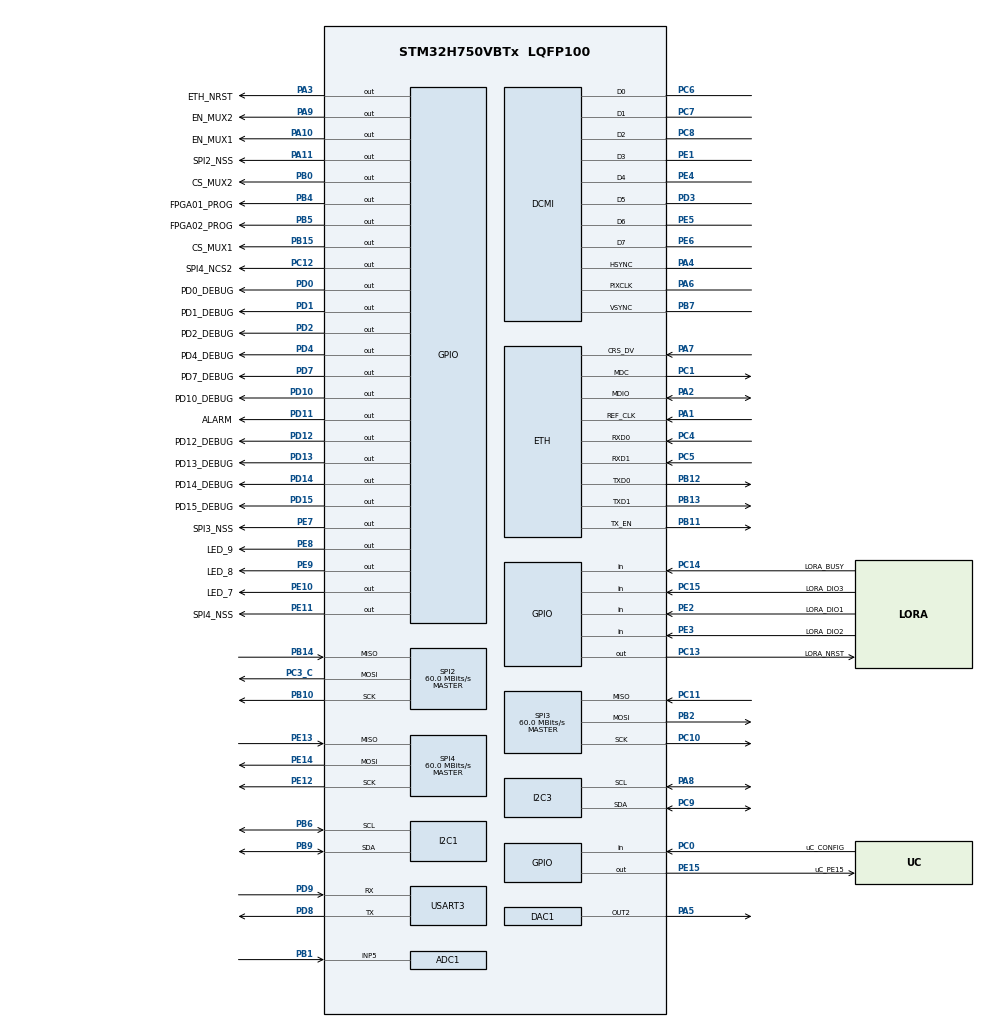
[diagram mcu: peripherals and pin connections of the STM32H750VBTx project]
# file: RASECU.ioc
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ADC1.Channel-0\#ChannelRegularConversion=ADC_CHANNEL_5
ADC1.NbrOfConversionFlag=1
ADC1.OffsetNumber-0\#ChannelRegularConversion=ADC_OFFSET_NONE
ADC1.OffsetSignedSaturation-0\#ChannelRegularConversion=DISABLE
ADC1.Rank-0\#ChannelRegularConversion=1
ADC1.SamplingTime-0\#ChannelRegularConversion=ADC_SAMPLETIME_1CYCLE_5
ADC1.master=1
CORTEX_M7.default_mode_Activation=1
DAC1.DAC_Channel-DAC_OUT2=DAC_CHANNEL_2
DCMI.HSPolarity=DCMI_HSPOLARITY_HIGH
DCMI.VSPolarity=DCMI_VSPOLARITY_HIGH
Dma.DCMI.0.Direction=DMA_PERIPH_TO_MEMORY
Dma.DCMI.0.EventEnable=DISABLE
Dma.DCMI.0.FIFOMode=DMA_FIFOMODE_ENABLE
Dma.DCMI.0.FIFOThreshold=DMA_FIFO_THRESHOLD_FULL
Dma.DCMI.0.Instance=DMA1_Stream0
Dma.DCMI.0.MemBurst=DMA_MBURST_INC4
Dma.DCMI.0.MemDataAlignment=DMA_MDATAALIGN_WORD
Dma.DCMI.0.MemInc=DMA_MINC_ENABLE
Dma.DCMI.0.Mode=DMA_CIRCULAR
Dma.DCMI.0.PeriphBurst=DMA_PBURST_SINGLE
Dma.DCMI.0.PeriphDataAlignment=DMA_PDATAALIGN_WORD
Dma.DCMI.0.PeriphInc=DMA_PINC_DISABLE
Dma.DCMI.0.Polarity=HAL_DMAMUX_REQ_GEN_RISING
Dma.DCMI.0.Priority=DMA_PRIORITY_VERY_HIGH
Dma.DCMI.0.RequestNumber=1
Dma.DCMI.0.SignalID=NONE
Dma.DCMI.0.SyncEnable=DISABLE
Dma.DCMI.0.SyncPolarity=HAL_DMAMUX_SYNC_NO_EVENT
Dma.DCMI.0.SyncRequestNumber=1
Dma.DCMI.0.SyncSignalID=NONE
Dma.Request0=DCMI
ETH.MediaInterface=HAL_ETH_RMII_MODE
I2C1.Timing=0x307075B1
I2C3.Timing=0x307075B1
Mcu.Family=STM32H7
Mcu.Name=STM32H750VBTx
Mcu.Package=LQFP100
NVIC.DCMI_IRQn=true\:0\:0\:false\:false\:true\:true\:true\:true
NVIC.DMA1_Stream0_IRQn=true\:0\:0\:false\:false\:true\:false\:true\:true
NVIC.PriorityGroup=NVIC_PRIORITYGROUP_4
PA1.Mode=RMII
PA1.Signal=ETH_REF_CLK
PA10.GPIO_Label=EN_MUX1
PA10.Signal=GPIO_Output
PA11.GPIO_Label=SPI2_NSS
PA11.Signal=GPIO_Output
PA13\ (JTMS/SWDIO).Mode=JTAG_4_pins
PA13\ (JTMS/SWDIO).Signal=DEBUG_JTMS-SWDIO
PA14\ (JTCK/SWCLK).Mode=JTAG_4_pins
PA14\ (JTCK/SWCLK).Signal=DEBUG_JTCK-SWCLK
PA15\ (JTDI).Mode=JTAG_4_pins
PA15\ (JTDI).Signal=DEBUG_JTDI
PA2.Mode=RMII
PA2.Signal=ETH_MDIO
PA3.GPIO_Label=ETH_NRST
PA3.Signal=GPIO_Output
PA4.GPIO_PuPd=GPIO_NOPULL
PA4.Mode=Slave_8_bits_External_Synchro
PA4.Signal=DCMI_HSYNC
PA5.Signal=COMP_DAC12_group
PA6.Mode=Slave_8_bits_External_Synchro
PA6.Signal=DCMI_PIXCLK
PA7.Mode=RMII
PA7.Signal=ETH_CRS_DV
PA8.Mode=I2C
PA8.Signal=I2C3_SCL
PA9.GPIO_Label=EN_MUX2
PA9.Signal=GPIO_Output
PB0.GPIO_Label=CS_MUX2
PB0.Signal=GPIO_Output
PB1.Signal=ADCx_INP5
PB10.Mode=Full_Duplex_Master
PB10.Signal=SPI2_SCK
PB11.Mode=RMII
PB11.Signal=ETH_TX_EN
PB12.Mode=RMII
PB12.Signal=ETH_TXD0
PB13.Mode=RMII
PB13.Signal=ETH_TXD1
PB14.Mode=Full_Duplex_Master
PB14.Signal=SPI2_MISO
PB15.GPIO_Label=CS_MUX1
PB15.Signal=GPIO_Output
PB2.Mode=Full_Duplex_Master
PB2.Signal=SPI3_MOSI
PB3\ (JTDO/TRACESWO).Mode=JTAG_4_pins
PB3\ (JTDO/TRACESWO).Signal=DEBUG_JTDO-SWO
PB4\ (NJTRST).GPIO_Label=FPGA01_PROG
PB4\ (NJTRST).Signal=GPIO_Output
PB5.GPIO_Label=FPGA02_PROG
PB5.Signal=GPIO_Output
PB6.GPIO_Pu=GPIO_PULLUP
PB6.Mode=I2C
PB6.Signal=I2C1_SCL
PB7.Mode=Slave_8_bits_External_Synchro
PB7.Signal=DCMI_VSYNC
PB9.Mode=I2C
PB9.Signal=I2C1_SDA
PC0.GPIO_Label=uC_CONFIG
PC0.Signal=GPIO_Input
PC1.Mode=RMII
PC1.Signal=ETH_MDC
PC10.Mode=Full_Duplex_Master
PC10.Signal=SPI3_SCK
PC11.Mode=Full_Duplex_Master
PC11.Signal=SPI3_MISO
PC12.GPIO_Label=SPI4_NCS2
PC12.Signal=GPIO_Output
PC13.GPIO_Label=LORA_NRST
PC13.Signal=GPIO_Output
PC14-OSC32_IN\ (OSC32_IN).GPIO_Label=LORA_BUSY
PC14-OSC32_IN\ (OSC32_IN).Signal=GPIO_Input
PC15-OSC32_OUT\ (OSC32_OUT).GPIO_Label=LORA_DIO3
PC15-OSC32_OUT\ (OSC32_OUT).Signal=GPIO_Input
PC3_C.Mode=Full_Duplex_Master
PC3_C.Signal=SPI2_MOSI
PC4.Mode=RMII
PC4.Signal=ETH_RXD0
PC5.Mode=RMII
PC5.Signal=ETH_RXD1
PC6.Mode=Slave_8_bits_External_Synchro
PC6.Signal=DCMI_D0
PC7.Mode=Slave_8_bits_External_Synchro
PC7.Signal=DCMI_D1
PC8.Mode=Slave_8_bits_External_Synchro
PC8.Signal=DCMI_D2
PC9.Mode=I2C
PC9.Signal=I2C3_SDA
PD0.GPIO_Label=PD0_DEBUG
PD0.Signal=GPIO_Output
PD1.GPIO_Label=PD1_DEBUG
PD1.Signal=GPIO_Output
PD10.GPIO_Label=PD10_DEBUG
PD10.Signal=GPIO_Output
PD11.GPIO_Label=ALARM
PD11.Signal=GPIO_Output
PD12.GPIO_Label=PD12_DEBUG
PD12.Signal=GPIO_Output
PD13.GPIO_Label=PD13_DEBUG
PD13.Signal=GPIO_Output
PD14.GPIO_Label=PD14_DEBUG
PD14.Signal=GPIO_Output
PD15.GPIO_Label=PD15_DEBUG
PD15.Signal=GPIO_Output
PD2.GPIO_Label=PD2_DEBUG
PD2.Signal=GPIO_Output
PD3.Mode=Slave_8_bits_External_Synchro
PD3.Signal=DCMI_D5
PD4.GPIO_Label=PD4_DEBUG
PD4.Signal=GPIO_Output
PD7.GPIO_Label=PD7_DEBUG
PD7.Signal=GPIO_Output
PD8.Mode=Asynchronous
PD8.Signal=USART3_TX
PD9.Mode=Asynchronous
PD9.Signal=USART3_RX
PE1.Mode=Slave_8_bits_External_Synchro
PE1.Signal=DCMI_D3
PE10.GPIO_Label=LED_7
PE10.Signal=GPIO_Output
PE11.GPIO_Label=SPI4_NSS
PE11.Signal=GPIO_Output
PE12.Mode=Full_Duplex_Master
PE12.Signal=SPI4_SCK
PE13.Mode=Full_Duplex_Master
PE13.Signal=SPI4_MISO
PE14.Mode=Full_Duplex_Master
PE14.Signal=SPI4_MOSI
PE15.GPIO_Label=uC_PE15
PE15.Signal=GPIO_Output
PE2.GPIO_Label=LORA_DIO1
PE2.Signal=GPIO_Input
PE3.GPIO_Label=LORA_DIO2
PE3.Signal=GPIO_Input
PE4.Mode=Slave_8_bits_External_Synchro
PE4.Signal=DCMI_D4
PE5.Mode=Slave_8_bits_External_Synchro
PE5.Signal=DCMI_D6
PE6.Mode=Slave_8_bits_External_Synchro
PE6.Signal=DCMI_D7
PE7.GPIO_Label=SPI3_NSS
PE7.Signal=GPIO_Output
PE8.GPIO_Label=LED_9
PE8.Signal=GPIO_Output
PE9.GPIO_Label=LED_8
PE9.Signal=GPIO_Output
PH0-OSC_IN\ (PH0).Mode=HSE-External-Oscillator
PH0-OSC_IN\ (PH0).Signal=RCC_OSC_IN
PH1-OSC_OUT\ (PH1).Mode=HSE-External-Oscillator
PH1-OSC_OUT\ (PH1).Signal=RCC_OSC_OUT
ProjectManager.HeapSize=0x200
ProjectManager.StackSize=0x400
ProjectManager.TargetToolchain=EWARM V8.50
RCC.ADCFreq_Value=75000000
RCC.APB1Freq_Value=120000000
RCC.APB2Freq_Value=120000000
RCC.APB3Freq_Value=120000000
RCC.APB4Freq_Value=120000000
RCC.CortexFreq_Value=480000000
RCC.D1PPRE=RCC_APB3_DIV2
RCC.D2PPRE1=RCC_APB1_DIV2
RCC.D2PPRE2=RCC_APB2_DIV2
RCC.D3PPRE=RCC_APB4_DIV2
RCC.DIVM1=2
RCC.DIVM2=2
RCC.DIVN1=96
RCC.DIVN2=15
RCC.DIVQ1=8
RCC.DIVQ2=3
RCC.DIVR1=4
RCC.HCLKFreq_Value=240000000
RCC.HPRE=RCC_HCLK_DIV2
RCC.HSE_VALUE=20000000
RCC.PLL2FRACN=0
RCC.PLLFRACN=0
RCC.PLLSourceVirtual=RCC_PLLSOURCE_HSE
RCC.SYSCLKFreq_VALUE=480000000
RCC.SYSCLKSource=RCC_SYSCLKSOURCE_PLLCLK
RCC.USART234578CLockSelection=RCC_USART234578CLKSOURCE_PLL2
RCC.USBFreq_Value=120000000
SH.ADCx_INP5.0=ADC1_INP5,IN5-Single-Ended
SH.COMP_DAC12_group.0=DAC1_OUT2,DAC_OUT2
SPI2.CalculateBaudRate=60.0 MBits/s
SPI2.Direction=SPI_DIRECTION_2LINES
SPI2.Mode=SPI_MODE_MASTER
SPI2.VirtualType=VM_MASTER
SPI3.CalculateBaudRate=60.0 MBits/s
SPI3.Direction=SPI_DIRECTION_2LINES
SPI3.Mode=SPI_MODE_MASTER
SPI3.VirtualType=VM_MASTER
SPI4.CalculateBaudRate=60.0 MBits/s
SPI4.Direction=SPI_DIRECTION_2LINES
SPI4.Mode=SPI_MODE_MASTER
SPI4.VirtualType=VM_MASTER
USART3.VirtualMode-Asynchronous=VM_ASYNC
board=custom

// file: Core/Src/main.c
/* USER CODE BEGIN Header */
/**
  ******************************************************************************
  * @file           : main.c
  * @brief          : Main program body
  ******************************************************************************
  * @attention
  *
  * Copyright (c) 2024 STMicroelectronics.
  * All rights reserved.
  *
  * This software is licensed under terms that can be found in the LICENSE file
  * in the root directory of this software component.
  * If no LICENSE file comes with this software, it is provided AS-IS.
  *
  ******************************************************************************
  */
/* USER CODE END Header */
#include "main.h"
#include "adc.h"
#include "dac.h"
#include "dcmi.h"
#include "dma.h"
#include "eth.h"
#include "i2c.h"
#include "spi.h"
#include "usart.h"
#include "gpio.h"

/* USER CODE BEGIN Includes */
#include <stdio.h>
#include <string.h>
#include "platform_types.h"
#include "802_11.h"
/* USER CODE END Includes */

/* USER CODE BEGIN PD */
#define CR_POWER_THRES                  3
#define CR_POWER_WINDOW                 4
#define CR_SKIP_SAMPLE                  5
#define SR_MIN_PLATEAU                  6

#define DCMI_META_SIZE  256
#define DCMI_FRAMESIZE  (DCMI_META_SIZE + 64)

/* USER CODE END PD */

/* USER CODE BEGIN PV */
u8 frameBuffer[DCMI_FRAMESIZE] @ "SRAM1";

/* USER CODE END PV */

void SystemClock_Config(void);
void PeriphCommonClock_Config(void);
static void MPU_Config(void);
/* USER CODE BEGIN PFP */

static void printMAC(u8 *pMac)
{
  printf("%02X:%02X:%02X:%02X:%02X:%02X", pMac[0], pMac[1], pMac[2], pMac[3], pMac[4], pMac[5] );
}

/* USER CODE END PFP */

/* USER CODE BEGIN 0 */
/**
 * \brief Outputs a character on the CONSOLE.
 *
 * \param c  Character to output.
 *
 * \return The character that was output.
 */
extern /*WEAK*/ signed int putchar( signed int c )
{
	if(c > 0xc0) {
		c = '.';
	}
  HAL_UART_Transmit(&huart3, (uint8_t*)&c, 1, 1000);
	return c ;
}

volatile u8 frameReadyFlag = 0;

void HAL_DCMI_FrameEventCallback(DCMI_HandleTypeDef *hdcmi)
{
    frameReadyFlag = 1;  // Set flag to indicate a new frame is ready
}

/* USER CODE END 0 */

int main(void)
{

  /* MPU Configuration--------------------------------------------------------*/
  MPU_Config();

  /* MCU Configuration--------------------------------------------------------*/

  /* Reset of all peripherals, Initializes the Flash interface and the Systick. */
  HAL_Init();

  /* Configure the system clock */
  SystemClock_Config();

/* Configure the peripherals common clocks */
  PeriphCommonClock_Config();

  /* Initialize all configured peripherals */
  MX_GPIO_Init();
  MX_DMA_Init();
  MX_DCMI_Init();
  MX_USART3_UART_Init();
  MX_ADC1_Init();
  MX_DAC1_Init();
  MX_ETH_Init();
  MX_I2C1_Init();
  MX_I2C3_Init();
  MX_SPI2_Init();
  MX_SPI3_Init();
  MX_SPI4_Init();
  /* USER CODE BEGIN 2 */
  u8 inData[5];
  u8 outData[5];
  u8 minPlateau = 100;
  u8 powerThres = 30;
  u8 powerWnd = 100;

  printf("Initialising OWIFI_RX chip.\n");

  outData[0] = CR_POWER_THRES << 1;
  outData[1] = 0;
  outData[2] = 0;
  outData[3] = 0;
  outData[4] = powerThres;
  HAL_SPI_TransmitReceive(&hspi4, outData, inData, 5, 1000);

  HAL_Delay(20);

  outData[0] = CR_POWER_WINDOW << 1;
  outData[1] = 0x00;
  outData[2] = 0x00;
  outData[3] = 0x00;
  outData[4] = powerWnd;
  HAL_SPI_TransmitReceive(&hspi4, outData, inData, 5, 1000);

  HAL_Delay(20);

  outData[0] = SR_MIN_PLATEAU << 1;
  outData[1] = 0x00;
  outData[2] = 0x00;
  outData[3] = 0x00;
  outData[4] = minPlateau;
  HAL_SPI_TransmitReceive(&hspi4, outData, inData, 5, 1000);

  HAL_Delay(20);

  outData[0] = CR_POWER_THRES <<1 | 1;
  outData[1] = 0;
  outData[2] = 0;
  outData[3] = 0;
  outData[4] = 0;
  HAL_SPI_TransmitReceive(&hspi4, outData, inData, 5, 1000);
  printf("Reg 3: %X %X %X %X\n", inData[1], inData[2], inData[3], inData[4] );

  HAL_Delay(20);

  outData[0] = CR_POWER_WINDOW <<1 | 1;
  outData[1] = 0;
  outData[2] = 0;
  outData[3] = 0;
  outData[4] = 0;
  HAL_SPI_TransmitReceive(&hspi4, outData, inData, 5, 1000);
  printf("Reg 4: %X %X %X %X\n", inData[1], inData[2], inData[3], inData[4] );

  HAL_DCMI_StateTypeDef dcmi_lastState, dcmi_state;

  memset(frameBuffer, 0xDD, sizeof(frameBuffer));

  __enable_irq();

  if(HAL_DCMI_Start_DMA(&hdcmi, DCMI_MODE_SNAPSHOT, (uint32_t)frameBuffer, DCMI_FRAMESIZE/4) != HAL_OK) {
      printf("ERROR DCMI DMA START!\n");
  }
  u8 *pHdr;

  /* USER CODE END 2 */

  /* Infinite loop */
  while (1)
  {

    /* USER CODE BEGIN 3 */

    if (frameReadyFlag == 1) {

      pHdr = &frameBuffer[259];

      DOT11_FHDR_FCTL1_T *pHdr1 = (DOT11_FHDR_FCTL1_T*) pHdr;
      pHdr += sizeof(DOT11_FHDR_FCTL1_T);
      DOT11_FHDR_FCTL0_T *pHdr0 = (DOT11_FHDR_FCTL0_T*) pHdr;
      pHdr += sizeof(DOT11_FHDR_FCTL1_T);

      printf("=============================================\n");
      printf("Timestamp: %ul\n", HAL_GetTick());
      printf("Protocol Version: %i\n", pHdr0->protoVersion);
      printf("Frame Type: %i\n", pHdr0->type);
      printf("Subtype: %i\n", pHdr0->subType);
      printf("To DS: %i\n", pHdr1->toDS);
      printf("From DS: %i\n", pHdr1->fromDS);
      printf("More Frag.: %i\n", pHdr1->moreFrag);
      printf("Retry: %i\n", pHdr1->retry);
      printf("Power Mgmt: %i\n", pHdr1->powerMng);
      printf("WEP: %i\n", pHdr1->WEP);
      printf("Order: %i\n", pHdr1->order);
      printf("Duration ID: %i\n", pHdr[0] + (pHdr[1]<<8));
      pHdr += 2;
      if(pHdr1->toDS) {
        printf("Destination MAC: ");
        printMAC(pHdr);
        printf("\n");
        pHdr += 6;
      }
      if(pHdr1->fromDS) {
        printf("Source MAC: ");
        printMAC(pHdr);
        printf("\n");
        pHdr += 6;
      }
      printf("---------------------------------------------\n");
      for(int i = 0; i < DCMI_META_SIZE; i++) {
        printf("%i,", (s8)frameBuffer[i]);
      }
      printf("\n\n");
      HAL_Delay(200);
      frameReadyFlag = 0;

    }
    // Error starting DCMI capture
    dcmi_state = HAL_DCMI_GetState(&hdcmi);
    if(dcmi_state != dcmi_lastState) {
      //printf("DCMI state: %i\n", dcmi_state);
      dcmi_lastState = dcmi_state;
    }
    if(dcmi_state == HAL_DCMI_STATE_ERROR || dcmi_state == HAL_DCMI_STATE_READY) {
      HAL_DCMI_Stop(&hdcmi);
      HAL_DCMI_Start_DMA(&hdcmi, DCMI_MODE_SNAPSHOT, (uint32_t)frameBuffer, DCMI_FRAMESIZE/4);
    }
  }
  /* USER CODE END 3 */
}

void SystemClock_Config(void)
{
  RCC_OscInitTypeDef RCC_OscInitStruct = {0};
  RCC_ClkInitTypeDef RCC_ClkInitStruct = {0};

  /** Supply configuration update enable
  */
  HAL_PWREx_ConfigSupply(PWR_LDO_SUPPLY);

  /** Configure the main internal regulator output voltage
  */
  __HAL_PWR_VOLTAGESCALING_CONFIG(PWR_REGULATOR_VOLTAGE_SCALE1);

  while(!__HAL_PWR_GET_FLAG(PWR_FLAG_VOSRDY)) {}

  __HAL_RCC_SYSCFG_CLK_ENABLE();
  __HAL_PWR_VOLTAGESCALING_CONFIG(PWR_REGULATOR_VOLTAGE_SCALE0);

  while(!__HAL_PWR_GET_FLAG(PWR_FLAG_VOSRDY)) {}

  /** Initializes the RCC Oscillators according to the specified parameters
  * in the RCC_OscInitTypeDef structure.
  */
  RCC_OscInitStruct.OscillatorType = RCC_OSCILLATORTYPE_HSE;
  RCC_OscInitStruct.HSEState = RCC_HSE_ON;
  RCC_OscInitStruct.PLL.PLLState = RCC_PLL_ON;
  RCC_OscInitStruct.PLL.PLLSource = RCC_PLLSOURCE_HSE;
  RCC_OscInitStruct.PLL.PLLM = 2;
  RCC_OscInitStruct.PLL.PLLN = 96;
  RCC_OscInitStruct.PLL.PLLP = 2;
  RCC_OscInitStruct.PLL.PLLQ = 8;
  RCC_OscInitStruct.PLL.PLLR = 4;
  RCC_OscInitStruct.PLL.PLLRGE = RCC_PLL1VCIRANGE_3;
  RCC_OscInitStruct.PLL.PLLVCOSEL = RCC_PLL1VCOWIDE;
  RCC_OscInitStruct.PLL.PLLFRACN = 0;
  if (HAL_RCC_OscConfig(&RCC_OscInitStruct) != HAL_OK)
  {
    Error_Handler();
  }

  /** Initializes the CPU, AHB and APB buses clocks
  */
  RCC_ClkInitStruct.ClockType = RCC_CLOCKTYPE_HCLK|RCC_CLOCKTYPE_SYSCLK
                              |RCC_CLOCKTYPE_PCLK1|RCC_CLOCKTYPE_PCLK2
                              |RCC_CLOCKTYPE_D3PCLK1|RCC_CLOCKTYPE_D1PCLK1;
  RCC_ClkInitStruct.SYSCLKSource = RCC_SYSCLKSOURCE_PLLCLK;
  RCC_ClkInitStruct.SYSCLKDivider = RCC_SYSCLK_DIV1;
  RCC_ClkInitStruct.AHBCLKDivider = RCC_HCLK_DIV2;
  RCC_ClkInitStruct.APB3CLKDivider = RCC_APB3_DIV2;
  RCC_ClkInitStruct.APB1CLKDivider = RCC_APB1_DIV2;
  RCC_ClkInitStruct.APB2CLKDivider = RCC_APB2_DIV2;
  RCC_ClkInitStruct.APB4CLKDivider = RCC_APB4_DIV2;

  if (HAL_RCC_ClockConfig(&RCC_ClkInitStruct, FLASH_LATENCY_4) != HAL_OK)
  {
    Error_Handler();
  }
}

void PeriphCommonClock_Config(void)
{
  RCC_PeriphCLKInitTypeDef PeriphClkInitStruct = {0};

  /** Initializes the peripherals clock
  */
  PeriphClkInitStruct.PeriphClockSelection = RCC_PERIPHCLK_ADC|RCC_PERIPHCLK_USART3;
  PeriphClkInitStruct.PLL2.PLL2M = 2;
  PeriphClkInitStruct.PLL2.PLL2N = 15;
  PeriphClkInitStruct.PLL2.PLL2P = 2;
  PeriphClkInitStruct.PLL2.PLL2Q = 3;
  PeriphClkInitStruct.PLL2.PLL2R = 2;
  PeriphClkInitStruct.PLL2.PLL2RGE = RCC_PLL2VCIRANGE_3;
  PeriphClkInitStruct.PLL2.PLL2VCOSEL = RCC_PLL2VCOMEDIUM;
  PeriphClkInitStruct.PLL2.PLL2FRACN = 0;
  PeriphClkInitStruct.Usart234578ClockSelection = RCC_USART234578CLKSOURCE_PLL2;
  PeriphClkInitStruct.AdcClockSelection = RCC_ADCCLKSOURCE_PLL2;
  if (HAL_RCCEx_PeriphCLKConfig(&PeriphClkInitStruct) != HAL_OK)
  {
    Error_Handler();
  }
}

 /* MPU Configuration */

void MPU_Config(void)
{
  MPU_Region_InitTypeDef MPU_InitStruct = {0};

  /* Disables the MPU */
  HAL_MPU_Disable();

  /** Initializes and configures the Region and the memory to be protected
  */
  MPU_InitStruct.Enable = MPU_REGION_ENABLE;
  MPU_InitStruct.Number = MPU_REGION_NUMBER0;
  MPU_InitStruct.BaseAddress = 0x0;
  MPU_InitStruct.Size = MPU_REGION_SIZE_4GB;
  MPU_InitStruct.SubRegionDisable = 0x87;
  MPU_InitStruct.TypeExtField = MPU_TEX_LEVEL0;
  MPU_InitStruct.AccessPermission = MPU_REGION_NO_ACCESS;
  MPU_InitStruct.DisableExec = MPU_INSTRUCTION_ACCESS_DISABLE;
  MPU_InitStruct.IsShareable = MPU_ACCESS_SHAREABLE;
  MPU_InitStruct.IsCacheable = MPU_ACCESS_NOT_CACHEABLE;
  MPU_InitStruct.IsBufferable = MPU_ACCESS_NOT_BUFFERABLE;

  HAL_MPU_ConfigRegion(&MPU_InitStruct);
  /* Enables the MPU */
  HAL_MPU_Enable(MPU_PRIVILEGED_DEFAULT);

}

void Error_Handler(void)
{
  __disable_irq();
  while (1)
  {
  }
}
